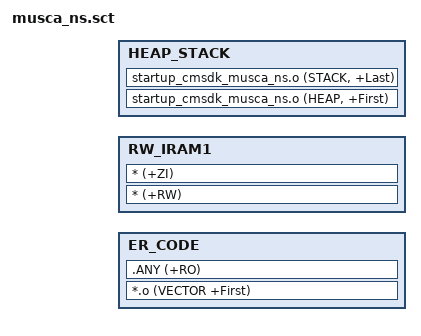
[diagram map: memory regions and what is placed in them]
#! armclang --target=arm-arm-none-eabi -march=armv8-m.main -E -xc

/*
 * Copyright (c) 2018 ARM Limited
 *
 * Licensed under the Apache License, Version 2.0 (the "License");
 * you may not use this file except in compliance with the License.
 * You may obtain a copy of the License at
 *
 *     http://www.apache.org/licenses/LICENSE-2.0
 *
 * Unless required by applicable law or agreed to in writing, software
 * distributed under the License is distributed on an "AS IS" BASIS,
 * WITHOUT WARRANTIES OR CONDITIONS OF ANY KIND, either express or implied.
 * See the License for the specific language governing permissions and
 * limitations under the License.
 */

#include "../../../partition/region_defs.h"
#include "../cmsis_nvic.h"

#if !defined(MBED_ROM_START)
  #define MBED_ROM_START    NS_CODE_START                           // 0x000a0400
#endif

#if !defined(MBED_ROM_SIZE)
  #define MBED_ROM_SIZE     NS_CODE_SIZE                            // 0x5f800
#endif

#if !defined(MBED_RAM_START)
  #define MBED_RAM_START    NVIC_RAM_VECTOR_LIMIT                   // 0x20010170
#endif

#if !defined(MBED_RAM_SIZE)
  #define MBED_RAM_SIZE     (NS_DATA_SIZE - NVIC_RAM_VECTOR_SIZE)   // 0xfe90
#endif

LR_CODE MBED_ROM_START NS_CODE_SIZE {
    ER_CODE MBED_ROM_START NS_CODE_SIZE {
        *.o (VECTOR +First)
        .ANY (+RO)
    }

    RW_IRAM1 MBED_RAM_START MBED_RAM_SIZE {
        * (+RW) ; RW data that gets copied from Flash to SRAM
        * (+ZI) ; ZI data that gets initialised to zero in SRAM
    }

    HEAP_STACK +0 ALIGN 8 {
        startup_cmsdk_musca_ns.o (HEAP, +First)
        startup_cmsdk_musca_ns.o (STACK, +Last)
    }
}

